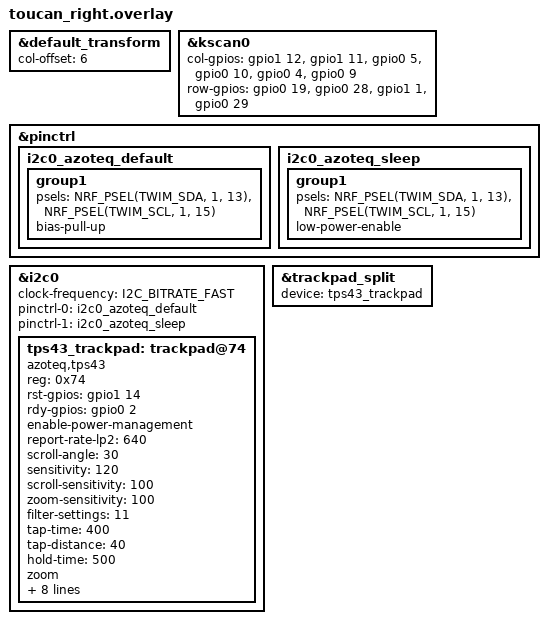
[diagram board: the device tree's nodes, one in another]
#include "toucan.dtsi"
#include <input/processors.dtsi>
#include <dt-bindings/zmk/input_transform.h>

&default_transform {
    col-offset = <6>;
};

&kscan0 {
    col-gpios
    = <&gpio1 12 GPIO_ACTIVE_HIGH>
    , <&gpio1 11 GPIO_ACTIVE_HIGH>
    , <&gpio0 5 GPIO_ACTIVE_HIGH>
    , <&gpio0 10 GPIO_ACTIVE_HIGH>
    , <&gpio0 4 GPIO_ACTIVE_HIGH>
    , <&gpio0 9 GPIO_ACTIVE_HIGH>
    ;

    row-gpios
    = <&gpio0 19 (GPIO_ACTIVE_HIGH | GPIO_PULL_DOWN)>
    , <&gpio0 28 (GPIO_ACTIVE_HIGH | GPIO_PULL_DOWN)>
    , <&gpio1 1 (GPIO_ACTIVE_HIGH | GPIO_PULL_DOWN)>
    , <&gpio0 29 (GPIO_ACTIVE_HIGH | GPIO_PULL_DOWN)>
    ;
};


&pinctrl {
    i2c0_azoteq_default: i2c0_azoteq_default {
        group1 {
            psels = <NRF_PSEL(TWIM_SDA, 1, 13)>,
                    <NRF_PSEL(TWIM_SCL, 1, 15)>;
            bias-pull-up;
        };
    };

    i2c0_azoteq_sleep: i2c0_azoteq_sleep {
        group1 {
            psels = <NRF_PSEL(TWIM_SDA, 1, 13)>,
                    <NRF_PSEL(TWIM_SCL, 1, 15)>;
            low-power-enable;
        };
    };
};

&i2c0 {
    status = "okay";
    clock-frequency = <I2C_BITRATE_FAST>;
    pinctrl-0 = <&i2c0_azoteq_default>;
    pinctrl-1 = <&i2c0_azoteq_sleep>;
    pinctrl-names = "default", "sleep";

    tps43_trackpad: trackpad@74 {
        compatible = "azoteq,tps43";
        reg = <0x74>;
        status = "okay";

        rst-gpios = <&gpio1 14 GPIO_ACTIVE_HIGH>;
        rdy-gpios = <&gpio0 2 GPIO_ACTIVE_HIGH>;

        enable-power-management;
        // idle-sleep; // maximal power savings, but the pad stops working while
                       // ZMK itself is idle (no key pressed for 30s). Not recommended.
        // timeout-lp1 = <3>; // 60s before entering lp2 (20s per unit, default 20s)
        report-rate-lp2 = <640>; // 640ms in LP2 = 55uA, vs 174uA at the default 160ms
        scroll-angle = <30>; // the default (~47 deg) is too coarse on the toucan
        // NOTE: these are movement multipliers (value/100), not touch
        // sensitivity - the driver scales the deltas by them.
        sensitivity = <120>;
        scroll-sensitivity = <100>;
        zoom-sensitivity = <100>;
        filter-settings = <11>;

        // Tap-to-click window. Left unset, the pad runs beekeeb's production
        // defaults, which are tight enough that a normal tap registers as
        // nothing at all: too slow for tap-time, too fast for hold-time.
        tap-time = <400>;     // a tap may keep contact this long (ms)
        tap-distance = <40>;  // and the finger may drift this far (px)
        hold-time = <500>;    // past this it is a press-and-hold (drag)

        zoom;
        scroll;
        two-finger-tap;
        single-tap;
        press-and-hold;
        //swipes;   // single-finger swipes: on, every cursor move fires a swipe
        three-finger-swipe;
        // A 3-finger swipe is derived from raw movement deltas on every touch
        // update, so one continuous motion can fire it repeatedly; the 300 ms
        // default is not enough to absorb a full sweep across the pad.
        three-finger-swipe-throttle-ms = <1200>;

        // Orientation of the pad on the board: the sensor's axes are rotated
        // 90 degrees relative to the keyboard, and its scroll axis runs the
        // other way.
        switch-xy;
        invert-scroll-y;
    };
};

&trackpad_split {
    device = <&tps43_trackpad>;
};

